# g2d_top: IP-XACT component
VLNV g2d:gpu:g2d_top:0.4.0
G2D 2D / 2.5D GPU IP (VGLite API compatible), Apache-2.0 WITH SHL-2.1. Ports at the default parameters (DATA_W 64, ADDR_W 32, ID_W 4); see docs/INTEGRATION.md.

## Ports
in clk_cfg_i
in rst_cfg_ni
in clk_i
in rst_ni
in clk_mem_i
in rst_mem_ni
in test_mode_i
in s_axil_awaddr_i[31:0]
in s_axil_awprot_i[2:0]
in s_axil_awvalid_i
out s_axil_awready_o
in s_axil_wdata_i[31:0]
in s_axil_wstrb_i[3:0]
in s_axil_wvalid_i
out s_axil_wready_o
out s_axil_bresp_o[1:0]
out s_axil_bvalid_o
in s_axil_bready_i
in s_axil_araddr_i[31:0]
in s_axil_arprot_i[2:0]
in s_axil_arvalid_i
out s_axil_arready_o
out s_axil_rdata_o[31:0]
out s_axil_rresp_o[1:0]
out s_axil_rvalid_o
in s_axil_rready_i
out m_axi_awid_o[3:0]
out m_axi_awaddr_o[31:0]
out m_axi_awlen_o[7:0]
out m_axi_awsize_o[2:0]
out m_axi_awburst_o[1:0]
out m_axi_awlock_o
out m_axi_awcache_o[3:0]
out m_axi_awprot_o[2:0]
out m_axi_awqos_o[3:0]
out m_axi_awregion_o[3:0]
out m_axi_awvalid_o
in m_axi_awready_i
out m_axi_wdata_o[63:0]
out m_axi_wstrb_o[7:0]
out m_axi_wlast_o
out m_axi_wvalid_o
in m_axi_wready_i
in m_axi_bid_i[3:0]
in m_axi_bresp_i[1:0]
in m_axi_bvalid_i
out m_axi_bready_o
out m_axi_arid_o[3:0]
out m_axi_araddr_o[31:0]
out m_axi_arlen_o[7:0]
out m_axi_arsize_o[2:0]
out m_axi_arburst_o[1:0]
out m_axi_arlock_o
out m_axi_arcache_o[3:0]
out m_axi_arprot_o[2:0]
out m_axi_arqos_o[3:0]
out m_axi_arregion_o[3:0]
out m_axi_arvalid_o
in m_axi_arready_i
in m_axi_rid_i[3:0]
in m_axi_rdata_i[63:0]
in m_axi_rresp_i[1:0]
in m_axi_rlast_i
in m_axi_rvalid_i
out m_axi_rready_o
out irq_o

## Address spaces and blocks
csr.g2d_csr: base 0, range 4096, width 32

## Registers
Registers are 32-bit, read-only, no defined reset value unless marked. A register's access mark holds for its fields unless they carry their own. Offsets are from the block's base; lines under a group give offsets from that group; [hi:lo] are bit positions; {n}, {i} and the like mark numbered series; 'fields as' and 'values as' point back to an identical list; <NAME> marks a mode.

## csr.g2d_csr
Base 0x00000000
0x00 ID reset 0x47324420 — IP identifier, ASCII "G2D ".
  [31:0] VALUE
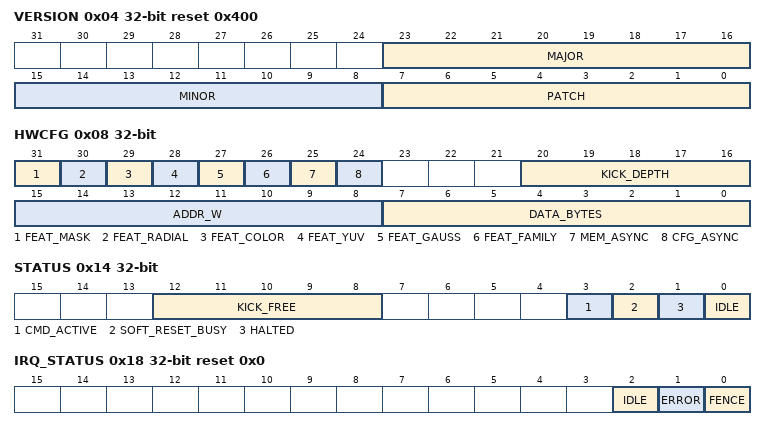
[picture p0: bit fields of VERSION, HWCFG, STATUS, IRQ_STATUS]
0x04 VERSION reset 0x400 — IP version (from the version key of this file).
  [23:16] MAJOR, [15:8] MINOR, [7:0] PATCH
0x08 HWCFG — Build-time configuration.
  [31] FEAT_MASK, [30] FEAT_RADIAL, [29] FEAT_COLOR, [28] FEAT_YUV, [27] FEAT_GAUSS, [26] FEAT_FAMILY, [25] MEM_ASYNC, [24] CFG_ASYNC, [20:16] KICK_DEPTH, [15:8] ADDR_W, [7:0] DATA_BYTES
0x0C SCRATCH rw reset 0x0 — Scratch register for bus tests.
  [31:0] VALUE
0x10 CTRL wo reset 0x0 — Control.
  [0] SOFT_RESET
0x14 STATUS
  [12:8] KICK_FREE, [3] CMD_ACTIVE, [2] SOFT_RESET_BUSY, [1] HALTED, [0] IDLE
0x18 IRQ_STATUS rw reset 0x0 — Interrupt status, write 1 to clear.
  [2] IDLE write-1-clears, [1] ERROR write-1-clears, [0] FENCE write-1-clears
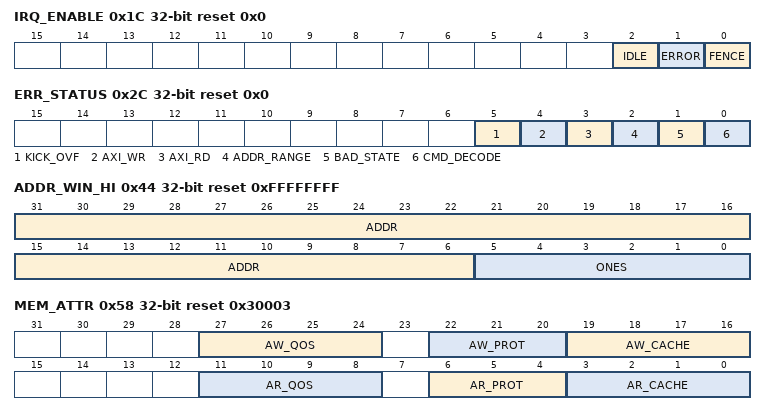
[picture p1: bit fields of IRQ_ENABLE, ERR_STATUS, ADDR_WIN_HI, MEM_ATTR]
0x1C IRQ_ENABLE rw reset 0x0 — Interrupt enable (same bit layout as IRQ_STATUS).
  [2] IDLE, [1] ERROR, [0] FENCE
0x20 CMD_ADDR rw reset 0x0 — Address of the next command buffer to kick (8-byte aligned).
  [31:3] ADDR
0x24 CMD_KICK wo reset 0x0 — Write pushes {CMD_ADDR, SIZE} into the kick queue.
  [23:0] SIZE
0x28 FENCE_SEQ — Value of the last completed FENCE command.
  [31:0] VALUE
0x2C ERR_STATUS rw reset 0x0 — Error flags (arch.md 8). Write 1 to clear; HALTED still needs a soft reset.
  [5] KICK_OVF write-1-clears, [4] AXI_WR write-1-clears, [3] AXI_RD write-1-clears, [2] ADDR_RANGE write-1-clears, [1] BAD_STATE write-1-clears, [0] CMD_DECODE write-1-clears
0x30 ERR_ADDR — Memory address of the first faulting transaction (low 32 bits).
0x34 ERR_CMD_ADDR — Address of the command header being executed when the first error occurred.
0x38 MEM_BASE_HI rw reset 0x0 — Upper AXI address bits [ADDR_W-1:32] for all GPU accesses (ignored when ADDR_W = 32).
  [31:0] ADDR
0x40 ADDR_WIN_LO rw reset 0x0 — Lowest permitted GPU address (inclusive), 64-byte granular (rendering.md 13.2).
  [31:6] ADDR
0x44 ADDR_WIN_HI access per field reset 0xFFFFFFFF — Highest permitted GPU address (inclusive); the low 6 bits always read as 1 (rendering.md 13.2).
  [31:6] ADDR rw, [5:0] ONES ro
0x48 CUR_CMD_ADDR — Address of the command word currently being parsed (debug).
0x4C DBG_CTRL wo reset 0x0 — Debug control (v1.8, arch.md 9.1).
  [0] SIG_CLEAR
0x50 DBG_STATUS rw reset 0x0 — Debug status (v1.8, arch.md 9.1). RAM_COLL bit i is set when on-chip RAM i was read and written at the same address in one cycle (undefined data on a real RAM; never happens by design): 0 raster edge buffer, 1 raster state buffers, 2 raster active list, 3 winding accumulator, 4 write combiner, 5 source cache, 6 gradient ramp. Write 1 to clear.
  [6:0] RAM_COLL write-1-clears
0x54 WR_SIG — Write signature (v1.8, arch.md 9.1): CRC-32 (IEEE 802.3, as zlib.crc32) over the bytes of every AXI W beat since reset or DBG_CTRL.SIG_CLEAR, byte lanes in order, lanes with WSTRB = 0 counted as 0x00. Not changed by a soft reset.
  [31:0] VALUE
0x58 MEM_ATTR rw reset 0x30003 — AXI attributes of the memory port (v1.9, arch.md 4.2). Used by every burst request issued after the write; a request already waiting on the bus keeps its values. Reset values are the fixed values of v1.0..v1.8 (normal non-cacheable bufferable, unprivileged secure data access, QoS 0).
  [27:24] AW_QOS, [22:20] AW_PROT, [19:16] AW_CACHE, [11:8] AR_QOS, [6:4] AR_PROT, [3:0] AR_CACHE
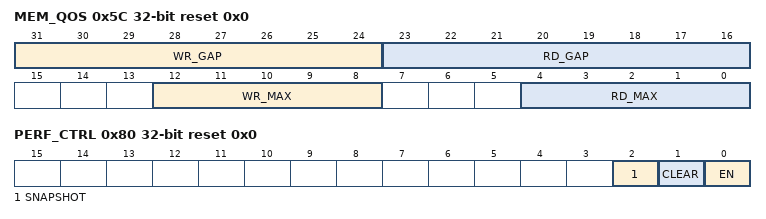
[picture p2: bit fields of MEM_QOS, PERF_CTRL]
0x5C MEM_QOS rw reset 0x0 — Memory-port throttle (v1.9, arch.md 4.2.1). RD_MAX / WR_MAX: at most this many read / write bursts outstanding (0 = only the build-time limit RD_OUTSTANDING / WR_OUTSTANDING). RD_GAP / WR_GAP: at least this many cycles without a request handshake after each AR / AW handshake (0 = none). Reset = off, which is cycle-identical to v1.8. A request already waiting on the bus is never withdrawn.
  [31:24] WR_GAP, [23:16] RD_GAP, [12:8] WR_MAX, [4:0] RD_MAX
0x80 PERF_CTRL access per field reset 0x0 — Performance counter control.
  [2] SNAPSHOT wo, [1] CLEAR wo, [0] EN rw
0x84 PERF_CYCLES — Cycles while EN.
  [31:0] VALUE
0x88 PERF_BUSY_CYCLES — Cycles while not IDLE.
  [31:0] VALUE
0x8C PERF_DRAWS — Draw commands completed.
  [31:0] VALUE
0x90 PERF_PIXELS_OUT — Pixels written.
  [31:0] VALUE
0x94 PERF_RD_BEATS — AXI R beats accepted.
  [31:0] VALUE
0x98 PERF_WR_BEATS — AXI W beats sent.
  [31:0] VALUE
0x9C PERF_RD_STALL — Cycles with AR or R back-pressure.
  [31:0] VALUE
0xA0 PERF_WR_STALL — Cycles with AW, W or B back-pressure.
  [31:0] VALUE
0xA4 PERF_DRAIN_CYC — Cycles spent in draw-ordering drains.
  [31:0] VALUE
0xA8 PERF_SRC_CACHE_MISS — Source cache line misses.
  [31:0] VALUE
